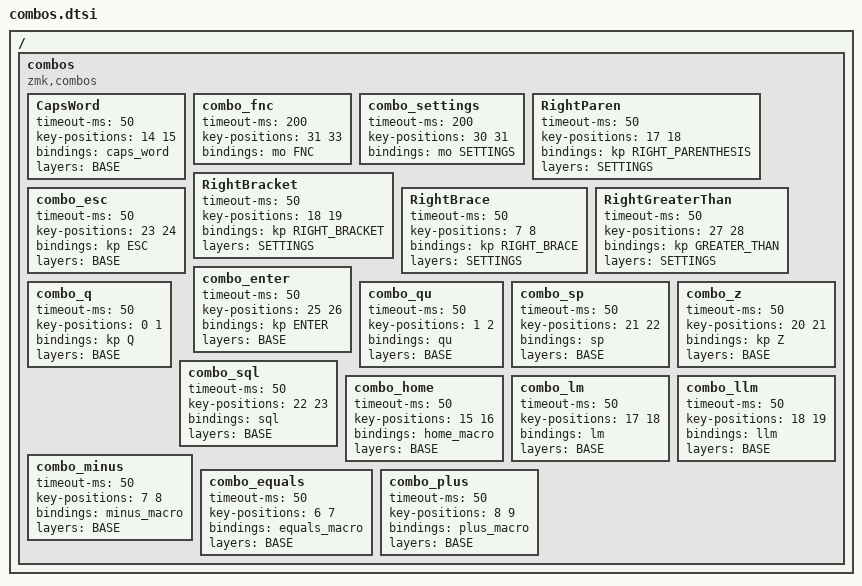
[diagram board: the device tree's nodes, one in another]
/ {
	combos {
		compatible = "zmk,combos";

		CapsWord {
			timeout-ms = <50>;
			key-positions = <14 15>;
			bindings = <&caps_word>;
			layers = <BASE>;
		};

		combo_fnc {
			timeout-ms = <200>;
			key-positions = <31 33>;
			bindings = <&mo FNC>;
		};

		combo_settings {
			timeout-ms = <200>;
			key-positions = <30 31>;
			bindings = <&mo SETTINGS>;
		};

		RightParen {
			timeout-ms = <50>;
			key-positions = <17 18>;
			bindings = <&kp RIGHT_PARENTHESIS>;
			layers = <SETTINGS>;
		};

		RightBracket {
			timeout-ms = <50>;
			key-positions = <18 19>;
			bindings = <&kp RIGHT_BRACKET>;
			layers = <SETTINGS>;
		};

		RightBrace {
			timeout-ms = <50>;
			key-positions = <7 8>;
			bindings = <&kp RIGHT_BRACE>;
			layers = <SETTINGS>;
		};

		RightGreaterThan {
			timeout-ms = <50>;
			key-positions = <27 28>;
			bindings = <&kp GREATER_THAN>;
			layers = <SETTINGS>;
		};

		combo_esc {
			timeout-ms = <50>;
			key-positions = <23 24>;
			bindings = <&kp ESC>;
			layers = <BASE>;
		};

		combo_enter {
			timeout-ms = <50>;
			key-positions = <25 26>;
			bindings = <&kp ENTER>;
			layers = <BASE>;
		};

		combo_q {
			timeout-ms = <50>;
			key-positions = <0 1>;
			bindings = <&kp Q>;
			layers = <BASE>;
		};

		combo_qu {
			timeout-ms = <50>;
			key-positions = <1 2>;
			bindings = <&qu>;
			layers = <BASE>;
		};

		combo_sp {
			timeout-ms = <50>;
			key-positions = <21 22>;
			bindings = <&sp>;
			layers = <BASE>;
		};

		combo_z {
			timeout-ms = <50>;
			key-positions = <20 21>;
			bindings = <&kp Z>;
			layers = <BASE>;
		};

		combo_sql {
			timeout-ms = <50>;
			key-positions = <22 23>;
			bindings = <&sql>;
			layers = <BASE>;
		};

		combo_home {
			timeout-ms = <50>;
			key-positions = <15 16>;
			bindings = <&home_macro>;
			layers = <BASE>;
		};

		combo_lm {
			timeout-ms = <50>;
			key-positions = <17 18>;
			bindings = <&lm>;
			layers = <BASE>;
		};

		combo_llm {
			timeout-ms = <50>;
			key-positions = <18 19>;
			bindings = <&llm>;
			layers = <BASE>;
		};

		combo_minus {
			timeout-ms = <50>;
			key-positions = <7 8>;
			bindings = <&minus_macro>;
			layers = <BASE>;
		};

		combo_equals {
			timeout-ms = <50>;
			key-positions = <6 7>;
			bindings = <&equals_macro>;
			layers = <BASE>;
		};

		combo_plus {
			timeout-ms = <50>;
			key-positions = <8 9>;
			bindings = <&plus_macro>;
			layers = <BASE>;
		};
	};
};
